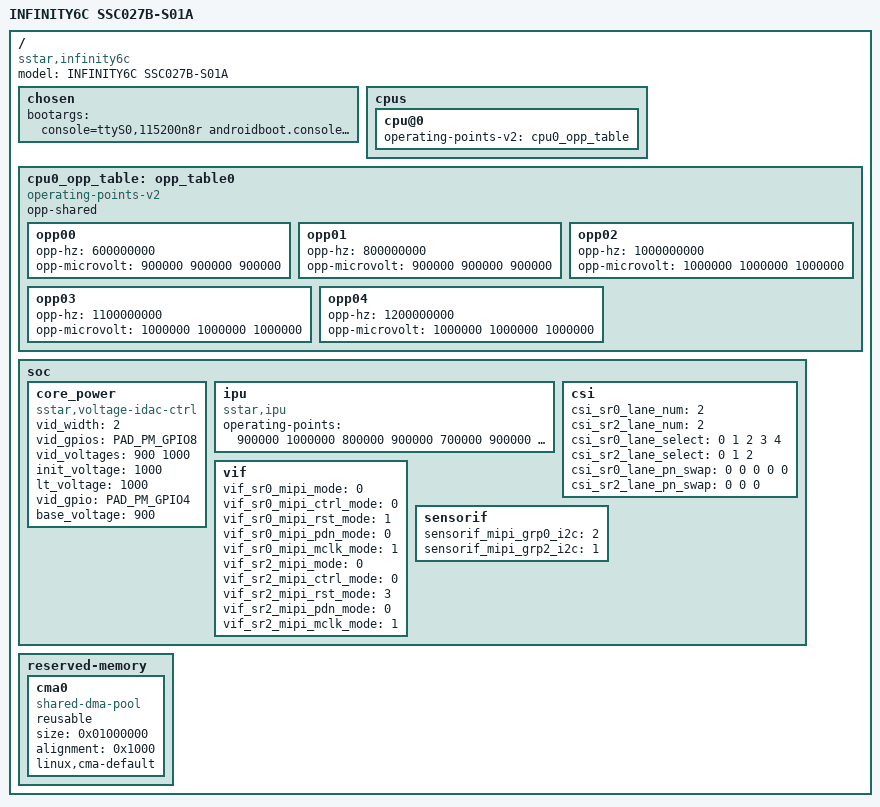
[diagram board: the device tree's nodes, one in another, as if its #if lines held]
/*
* infinity6c-ssc027b-s01a.dts - Sigmastar
*
* Copyright (c) [2019~2020] SigmaStar Technology.
*
*
* This software is licensed under the terms of the GNU General Public
* License version 2, as published by the Free Software Foundation, and
* may be copied, distributed, and modified under those terms.
*
* This program is distributed in the hope that it will be useful,
* but WITHOUT ANY WARRANTY; without even the implied warranty of
* MERCHANTABILITY or FITNESS FOR A PARTICULAR PURPOSE.  See the
* GNU General Public License version 2 for more details.
*
*/

 /*
 * Memory Layout
 * 0x20000000-0x24000000 64M Kernel
 * 0x24000000-0x24800000 8M  system
 * 0x24800000-0x24900000 1M  data
 * 0x24900000-0x25000000 7M  temp0
 * 0x25000000-0x28000000 48M temp1
 */
/dts-v1/;
#include "infinity6c.dtsi"
#include "infinity6c-ssc027b-s01a-padmux.dtsi"

/ {
    #address-cells = <1>;
    #size-cells = <1>;
    model = "INFINITY6C SSC027B-S01A";
    compatible = "sstar,infinity6c";

    chosen {
        bootargs = "console=ttyS0,115200n8r androidboot.console=ttyS0 user_debug=31 root=/dev/mtdblock0 init=/linuxrc LX_MEM=0x04000000 mma_heap=mma_heap_name0,miu=0,sz=0x2000000,max_start_off=0x22000000 mma_memblock_remove=1 cma=2M nohz=off";
    };

    cpus {
        cpu@0 {
            operating-points-v2 = <&cpu0_opp_table>;
        };
    };
    cpu0_opp_table: opp_table0 {
        compatible = "operating-points-v2";
        opp-shared;
        opp00 {
            opp-hz = /bits/ 64 <600000000>;
            opp-microvolt = <900000 900000 900000>;/* Supply 0 *//*uv(ss),uvmin(FF),uvmax(SS)*/
            status = "ok";
        };
        opp01 {
            opp-hz = /bits/ 64 <800000000>;
            opp-microvolt = <900000 900000 900000>;
            status = "ok";
        };
        opp02 {
            opp-hz = /bits/ 64 <1000000000>;
            opp-microvolt = <1000000 1000000 1000000>;
            status = "ok";
        };
        opp03 {
            opp-hz = /bits/ 64 <1100000000>;
            opp-microvolt = <1000000 1000000 1000000>;
            status = "ok";
        };
        opp04 {
            opp-hz = /bits/ 64 <1200000000>;
            opp-microvolt = <1000000 1000000 1000000>;
            status = "ok";
        };
    };

    soc {
#if CONFIG_SS_VOLTAGE_CTRL
        core_power {
            compatible = "sstar,voltage-ctrl";
            vid_width = <2>;
            vid_gpios = <PAD_PM_GPIO8>;
            vid_voltages = <900 1000>;
            init_voltage = <1000>;
            lt_voltage = <1000>;
            status = "ok";
        };
#endif
#if CONFIG_SS_VOLTAGE_IDAC_CTRL
        core_power {
            compatible = "sstar,voltage-idac-ctrl";
            vid_gpio = <PAD_PM_GPIO4>;
            base_voltage = <900>;
            init_voltage = <1000>;
            lt_voltage = <1000>;
            status = "ok";
        };
#endif
        ipu {
            compatible = "sstar,ipu";
            operating-points = <
                /* kHz     uV */
                900000   1000000
                800000    900000
                700000    900000
                600000    900000
                500000    900000
                400000    900000
                300000    900000
            >;
        };
        csi: csi {
            /* Config max lane number */
            csi_sr0_lane_num = <2>;
            csi_sr2_lane_num = <2>;

            /* Config lane selection */
            csi_sr0_lane_select = <0 1 2 3 4>;
            csi_sr2_lane_select = <0 1 2>;
            /* Config lane P/N swap */
            csi_sr0_lane_pn_swap = <0 0 0 0 0>;
            csi_sr2_lane_pn_swap = <0 0 0>;
        };
        vif: vif {
            /* Config sensor 0 pad mux */
            vif_sr0_mipi_mode         = <0>;
            vif_sr0_mipi_ctrl_mode    = <0>;
            vif_sr0_mipi_rst_mode     = <1>;
            vif_sr0_mipi_pdn_mode     = <0>;
            vif_sr0_mipi_mclk_mode    = <1>;

            /* Config sensor 2 pad mux */
            vif_sr2_mipi_mode         = <0>;
            vif_sr2_mipi_ctrl_mode    = <0>;
            vif_sr2_mipi_rst_mode     = <3>;
            vif_sr2_mipi_pdn_mode     = <0>;
            vif_sr2_mipi_mclk_mode    = <1>;
        };
        sensorif: sensorif {
            /* Config MIPI2+2 mapping I2C_ID */
            sensorif_mipi_grp0_i2c    = <2>;
            sensorif_mipi_grp2_i2c    = <1>;
        };
    };

/*!!IMPORTANT!! The reserved memory must be 1MB aligned*/
    reserved-memory {
        #address-cells = <1>;
        #size-cells = <1>;
        ranges;

        cma0 {
            compatible = "shared-dma-pool";
            reusable;
            size = <0x01000000>;
            alignment = <0x1000>;
            linux,cma-default;
        };
    };
};
